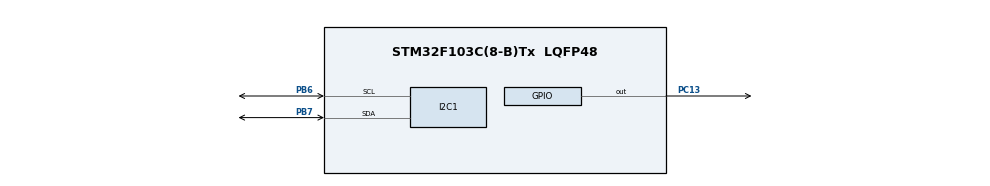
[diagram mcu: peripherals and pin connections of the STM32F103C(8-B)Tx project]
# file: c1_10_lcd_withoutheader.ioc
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Mcu.Family=STM32F1
Mcu.Name=STM32F103C(8-B)Tx
Mcu.Package=LQFP48
NVIC.PriorityGroup=NVIC_PRIORITYGROUP_4
PB6.Mode=I2C
PB6.Signal=I2C1_SCL
PB7.Mode=I2C
PB7.Signal=I2C1_SDA
PC13-TAMPER-RTC.Signal=GPIO_Output
ProjectManager.HeapSize=0x200
ProjectManager.StackSize=0x400
ProjectManager.TargetToolchain=STM32CubeIDE
RCC.APB1Freq_Value=8000000
RCC.APB2Freq_Value=8000000
VP_SYS_VS_ND.Mode=No_Debug
board=custom

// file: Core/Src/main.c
/* USER CODE BEGIN Header */
/**
  ******************************************************************************
  * @file           : main.c
  * @brief          : Main program body
  ******************************************************************************
  * @attention
  *
  * Copyright (c) 2025 STMicroelectronics.
  * All rights reserved.
  *
  * This software is licensed under terms that can be found in the LICENSE file
  * in the root directory of this software component.
  * If no LICENSE file comes with this software, it is provided AS-IS.
  *
  ******************************************************************************
  */
/* USER CODE END Header */
#include "main.h"

/* USER CODE BEGIN PTD */
#define DEVICE_ADDR (0x27<<1)
/* USER CODE END PTD */
uint8_t command1[]={0x30,0x30,0x30,0x20,'\0'};
uint8_t command[]={0x28,0x0E,0x01,0x07,0x8F,'\0'};

I2C_HandleTypeDef hi2c1;

void SystemClock_Config(void);
static void MX_GPIO_Init(void);
static void MX_I2C1_Init(void);
/* USER CODE BEGIN PFP */
void lcd_init(void);
void lcd_write_command1(uint8_t command_1);
void lcd_write_command(uint8_t data);
void lcd_write_data(uint8_t data);
void delay();
/* USER CODE END PFP */

int main(void)
{

  /* MCU Configuration--------------------------------------------------------*/

  /* Reset of all peripherals, Initializes the Flash interface and the Systick. */
  HAL_Init();

  /* Configure the system clock */
  SystemClock_Config();

  /* Initialize all configured peripherals */
  MX_GPIO_Init();
  MX_I2C1_Init();
  /* USER CODE BEGIN 2 */
  //HAL_I2C_Master_Transmit(&hi2c1, DEVICE_ADDR, (uint8_t*)&data, 1, 10);
  lcd_init();
  /* USER CODE END 2 */

  /* Infinite loop */
  while (1)
  {

    /* USER CODE BEGIN 3 */
	  lcd_write_command(0x8F);

	  lcd_write_data('E');
	  HAL_Delay(1000);
	  lcd_write_data('G');
	  HAL_Delay(1000);
	  lcd_write_data('S');
	  HAL_Delay(1000);

	  //HAL_Delay(1000);
	  //lcd_write_data('.');
	  HAL_GPIO_TogglePin(GPIOC,GPIO_PIN_13);
	  HAL_Delay(1000);
  }
  /* USER CODE END 3 */
}

void lcd_init(){
	uint8_t i=0;
	//while(command[i]!='\0'){
	//	lcd_write_command(command[i]);
	//	i++;
	//}
	for(i=0;i<4;i++){
			lcd_write_command1(command1[i]);

		}
	for(i=0;i<6;i++){
		lcd_write_command(command[i]);
		HAL_Delay(100);

	}
}

void lcd_write_command1(uint8_t command_1){
	uint8_t upper_nibble = command_1&0xF0;
	uint8_t backlight = 0x08;
	uint8_t en = 0x04;
	uint8_t rw = 0x02;
	uint8_t rs = 0x01;
	uint8_t packet = (upper_nibble | backlight | en) & ~(rw | rs);
	HAL_I2C_Master_Transmit(&hi2c1, DEVICE_ADDR, &packet, 1, 10);
	HAL_Delay(1);
	packet = (upper_nibble | backlight) & ~(en | rw | rs);
	HAL_I2C_Master_Transmit(&hi2c1, DEVICE_ADDR, &packet, 1, 10);
	HAL_Delay(5);
}

void lcd_write_command(uint8_t data){
	uint8_t upper_nibble = data&0xF0;
	uint8_t lower_nibble = (data<<4)&0xF0;
	uint8_t backlight = 0x08;
	uint8_t en = 0x04;
	uint8_t rw = 0x02;
	uint8_t rs = 0x01;

	//uint8_t packet1 = upper_nibble | backlight ;
	//packet1 = packet1 | en ;
	//packet1 = packet1 &(~(rw|rs))  ;
	uint8_t packet1 = (upper_nibble | backlight | en ) & ~(rw | rs);
	HAL_I2C_Master_Transmit(&hi2c1, DEVICE_ADDR, &packet1, 1, 10);
	HAL_Delay(2);
	packet1 = (upper_nibble | backlight ) & ~(en | rw | rs);
	HAL_I2C_Master_Transmit(&hi2c1, DEVICE_ADDR, &packet1, 1, 10);
	HAL_Delay(2);
	uint8_t packet2 = (lower_nibble | backlight | en ) & ~(rw | rs);
	HAL_I2C_Master_Transmit(&hi2c1, DEVICE_ADDR, &packet2, 1, 10);
	HAL_Delay(2);
	packet2 = (lower_nibble | backlight ) & ~(en | rw | rs);
	HAL_I2C_Master_Transmit(&hi2c1, DEVICE_ADDR, &packet2, 1, 10);
	HAL_Delay(2);

}

void lcd_write_data(uint8_t data){
	uint8_t upper_nibble = data&0xF0;
	uint8_t lower_nibble = (data<<4)&0xF0;
	uint8_t backlight = 0x08;
	uint8_t en = 0x04;
	uint8_t rw = 0x02;
	uint8_t rs = 0x01;

	//uint8_t packet1 = upper_nibble | backlight | rs ;
	//packet1 = packet1 | en ;
	//packet1 = packet1 &(~rw)  ;
	uint8_t packet1 = (upper_nibble | backlight | en | rs) & ~(rw);
	HAL_I2C_Master_Transmit(&hi2c1, DEVICE_ADDR, &packet1, 1, 10);
	HAL_Delay(2);
	//packet1 = packet1 &(~en)  ;
	packet1 = (upper_nibble | backlight | rs) & ~(en | rw);
	HAL_I2C_Master_Transmit(&hi2c1, DEVICE_ADDR, &packet1, 1, 10);
	HAL_Delay(2);

	uint8_t packet2 = (lower_nibble | backlight | en | rs) & ~(rw);
	HAL_I2C_Master_Transmit(&hi2c1, DEVICE_ADDR, &packet2, 1, 10);
	HAL_Delay(2);
	packet2 = (lower_nibble | backlight | rs) & ~(en | rw);
	HAL_I2C_Master_Transmit(&hi2c1, DEVICE_ADDR, &packet2, 1, 10);
	HAL_Delay(2);

}

void SystemClock_Config(void)
{
  RCC_OscInitTypeDef RCC_OscInitStruct = {0};
  RCC_ClkInitTypeDef RCC_ClkInitStruct = {0};

  /** Initializes the RCC Oscillators according to the specified parameters
  * in the RCC_OscInitTypeDef structure.
  */
  RCC_OscInitStruct.OscillatorType = RCC_OSCILLATORTYPE_HSI;
  RCC_OscInitStruct.HSIState = RCC_HSI_ON;
  RCC_OscInitStruct.HSICalibrationValue = RCC_HSICALIBRATION_DEFAULT;
  RCC_OscInitStruct.PLL.PLLState = RCC_PLL_NONE;
  if (HAL_RCC_OscConfig(&RCC_OscInitStruct) != HAL_OK)
  {
    Error_Handler();
  }

  /** Initializes the CPU, AHB and APB buses clocks
  */
  RCC_ClkInitStruct.ClockType = RCC_CLOCKTYPE_HCLK|RCC_CLOCKTYPE_SYSCLK
                              |RCC_CLOCKTYPE_PCLK1|RCC_CLOCKTYPE_PCLK2;
  RCC_ClkInitStruct.SYSCLKSource = RCC_SYSCLKSOURCE_HSI;
  RCC_ClkInitStruct.AHBCLKDivider = RCC_SYSCLK_DIV1;
  RCC_ClkInitStruct.APB1CLKDivider = RCC_HCLK_DIV1;
  RCC_ClkInitStruct.APB2CLKDivider = RCC_HCLK_DIV1;

  if (HAL_RCC_ClockConfig(&RCC_ClkInitStruct, FLASH_LATENCY_0) != HAL_OK)
  {
    Error_Handler();
  }
}

static void MX_I2C1_Init(void)
{

  hi2c1.Instance = I2C1;
  hi2c1.Init.ClockSpeed = 100000;
  hi2c1.Init.DutyCycle = I2C_DUTYCYCLE_2;
  hi2c1.Init.OwnAddress1 = 0;
  hi2c1.Init.AddressingMode = I2C_ADDRESSINGMODE_7BIT;
  hi2c1.Init.DualAddressMode = I2C_DUALADDRESS_DISABLE;
  hi2c1.Init.OwnAddress2 = 0;
  hi2c1.Init.GeneralCallMode = I2C_GENERALCALL_DISABLE;
  hi2c1.Init.NoStretchMode = I2C_NOSTRETCH_DISABLE;
  if (HAL_I2C_Init(&hi2c1) != HAL_OK)
  {
    Error_Handler();
  }

}

static void MX_GPIO_Init(void)
{
  GPIO_InitTypeDef GPIO_InitStruct = {0};

  /* GPIO Ports Clock Enable */
  __HAL_RCC_GPIOC_CLK_ENABLE();
  __HAL_RCC_GPIOB_CLK_ENABLE();

  /*Configure GPIO pin Output Level */
  HAL_GPIO_WritePin(GPIOC, GPIO_PIN_13, GPIO_PIN_RESET);

  /*Configure GPIO pin : PC13 */
  GPIO_InitStruct.Pin = GPIO_PIN_13;
  GPIO_InitStruct.Mode = GPIO_MODE_OUTPUT_PP;
  GPIO_InitStruct.Pull = GPIO_NOPULL;
  GPIO_InitStruct.Speed = GPIO_SPEED_FREQ_LOW;
  HAL_GPIO_Init(GPIOC, &GPIO_InitStruct);

}

void Error_Handler(void)
{
  __disable_irq();
  while (1)
  {
  }
}
